# APM32F465 register map
File version: 1.0
CPU: CM4 r1p0, little endian, no MPU, no FPU, 3 interrupt priority bits
Registers are 32-bit, read-write, reset 0x0 unless marked. A register's access mark holds for its fields unless they carry their own. Offsets are from the block's base; [hi:lo] are bit positions; {n}, {i} and the like mark numbered series.

## DMC — Dynamic memory controler
Base 0xA0000000; alternate view of SMC
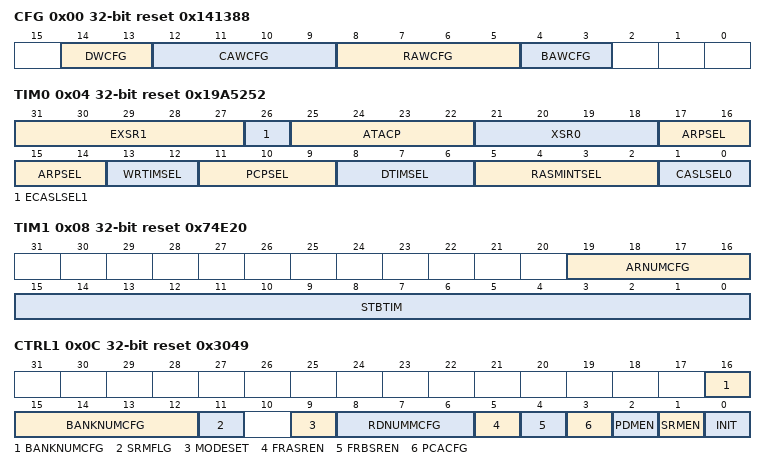
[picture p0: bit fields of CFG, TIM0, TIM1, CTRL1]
0x00 CFG reset 0x141388 — Configuraion register
  [14:13] DWCFG — Data Width Configure
  [12:9] CAWCFG — Column Address Width Configure
  [8:5] RAWCFG — Row Address Width Configure
  [4:3] BAWCFG — Bank Address Width Configure
0x04 TIM0 reset 0x19A5252 — Timing register 0
  [31:27] EXSR1
  [26] ECASLSEL1 — Extended CAS Latency
  [25:22] ATACP — Active to active
  [21:18] XSR0
  [17:14] ARPSEL — Auto-Refresh Period Select
  [13:12] WRTIMSEL
  [11:9] PCPSEL — Precharge Period Select
  [8:6] DTIMSEL — RAS To CAS Delay Time Select
  [5:2] RASMINTSEL — RAS Minimum Time Select
  [1:0] CASLSEL0 — CAS Latency Select
0x08 TIM1 reset 0x74E20 — Timing register 1
  [19:16] ARNUMCFG — Number Of Auto-Refresh During Initialization Configure
  [15:0] STBTIM — Stable Time
0x0C CTRL1 access per field reset 0x3049 — Control register 1
  [16:12] BANKNUMCFG rw — Number Of Open Banks Configure
  [11] SRMFLG ro — Self-refresh mode flag
  [9] MODESET rw — Mode Setup
  [8:6] RDNUMMCFG rw — Configure Number Of Registers Inserted In Read Data Path
  [5] FRASREN rw — Full Refresh After Exit Self-Refresh Mode
  [4] FRBSREN rw — Full Refresh Before Entering Self-Refresh Mode
  [3] PCACFG rw — Precharge Algorithm Configure
  [2] PDMEN rw — Put SDRM in Power-Down Mode Enable
  [1] SRMEN rw — Put SDRM in Self-Refresh Mode Enable
  [0] INIT rw — SDRAM Initialize
0x10 REF reset 0xC3 — refresh register
  [15:0] RCYCCFG
0x400 SW — switch register
  [0] MCSW — Memory Controller Function Switch
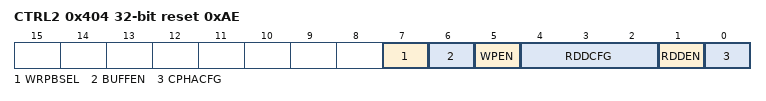
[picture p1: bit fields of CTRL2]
0x404 CTRL2 reset 0xAE — Control register 2
  [7] WRPBSEL, [6] BUFFEN, [5] WPEN, [4:2] RDDCFG, [1] RDDEN, [0] CPHACFG

## RNG — Random number generator
Base 0x50060800
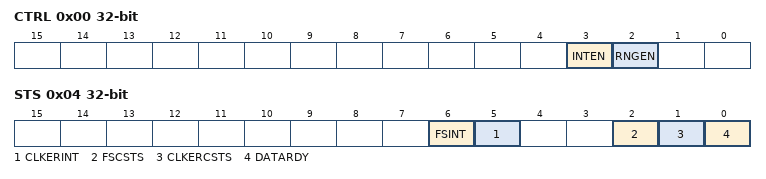
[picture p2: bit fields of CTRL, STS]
0x00 CTRL — control register
  [3] INTEN — Interrupt enable
  [2] RNGEN — Random number generator enable
0x04 STS access per field — status register
  [6] FSINT rw — Seed error interrupt status
  [5] CLKERINT rw — Clock error interrupt status
  [2] FSCSTS ro — Seed error current status
  [1] CLKERCSTS ro — Clock error current status
  [0] DATARDY ro — Data ready
0x08 DATA ro
  [31:0] DATA — Random data

## DCI — Digital camera interface
Base 0x50050000
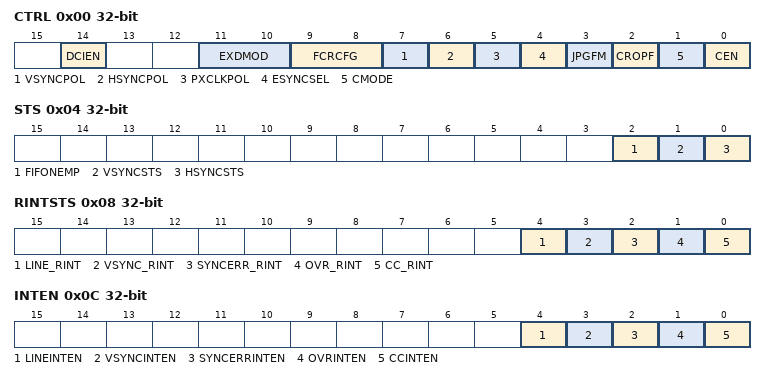
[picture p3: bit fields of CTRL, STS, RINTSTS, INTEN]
0x00 CTRL — control register 1
  [14] DCIEN — DCI enable
  [11:10] EXDMOD — Extended data mode
  [9:8] FCRCFG — Frame capture rate control
  [7] VSYNCPOL — Vertical synchronization polarity
  [6] HSYNCPOL — Horizontal synchronization polarity
  [5] PXCLKPOL — Pixel clock polarity
  [4] ESYNCSEL — Embedded synchronization select
  [3] JPGFM — JPEG format
  [2] CROPF — Crop feature
  [1] CMODE — Capture mode
  [0] CEN — Capture enable
0x04 STS ro — status register
  [2] FIFONEMP — FIFO not empty
  [1] VSYNCSTS
  [0] HSYNCSTS
0x08 RINTSTS ro — raw interrupt status register
  [4] LINE_RINT — Line raw interrupt status
  [3] VSYNC_RINT — VSYNC raw interrupt status
  [2] SYNCERR_RINT — Synchronization error raw interrupt status
  [1] OVR_RINT — Overrun raw interrupt status
  [0] CC_RINT — Capture complete raw interrupt status
0x0C INTEN — interrupt enable register
  [4] LINEINTEN — Line interrupt enable
  [3] VSYNCINTEN — VSYNC interrupt enable
  [2] SYNCERRINTEN — Synchronization error interrupt enable
  [1] OVRINTEN — Overrun interrupt enable
  [0] CCINTEN — Capture complete interrupt enable
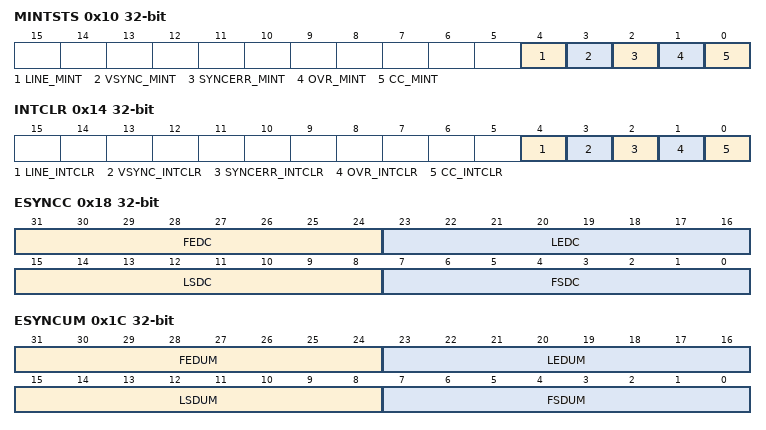
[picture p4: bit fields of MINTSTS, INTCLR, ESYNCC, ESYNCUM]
0x10 MINTSTS ro — masked interrupt status register
  [4] LINE_MINT — Line masked interrupt status
  [3] VSYNC_MINT — VSYNC masked interrupt status
  [2] SYNCERR_MINT — Synchronization error masked interrupt status
  [1] OVR_MINT — Overrun masked interrupt status
  [0] CC_MINT — Capture complete masked interrupt status
0x14 INTCLR wo — interrupt clear register
  [4] LINE_INTCLR — line interrupt status clear
  [3] VSYNC_INTCLR — Vertical synch interrupt status clear
  [2] SYNCERR_INTCLR — Synchronization error interrupt status clear
  [1] OVR_INTCLR — Overrun interrupt status clear
  [0] CC_INTCLR — Capture complete interrupt status clear
0x18 ESYNCC — embedded synchronization code register
  [31:24] FEDC — Frame end delimiter code
  [23:16] LEDC — Line end delimiter code
  [15:8] LSDC — Line start delimiter code
  [7:0] FSDC — Frame start delimiter code
0x1C ESYNCUM — embedded synchronization unmask register
  [31:24] FEDUM — Frame end delimiter unmask
  [23:16] LEDUM — Line end delimiter unmask
  [15:8] LSDUM — Line start delimiter unmask
  [7:0] FSDUM — Frame start delimiter unmask
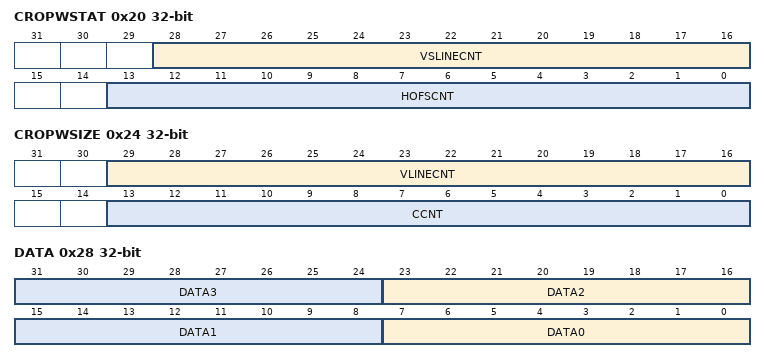
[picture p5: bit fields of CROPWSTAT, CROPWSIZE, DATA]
0x20 CROPWSTAT — crop window start
  [28:16] VSLINECNT — Vertical start line count
  [13:0] HOFSCNT — Horizontal offset count
0x24 CROPWSIZE — crop window size
  [29:16] VLINECNT — Vertical line count
  [13:0] CCNT — Capture count
0x28 DATA ro
  [8n+7:8n] DATA{n} (n=0..3) — Data byte {n}
